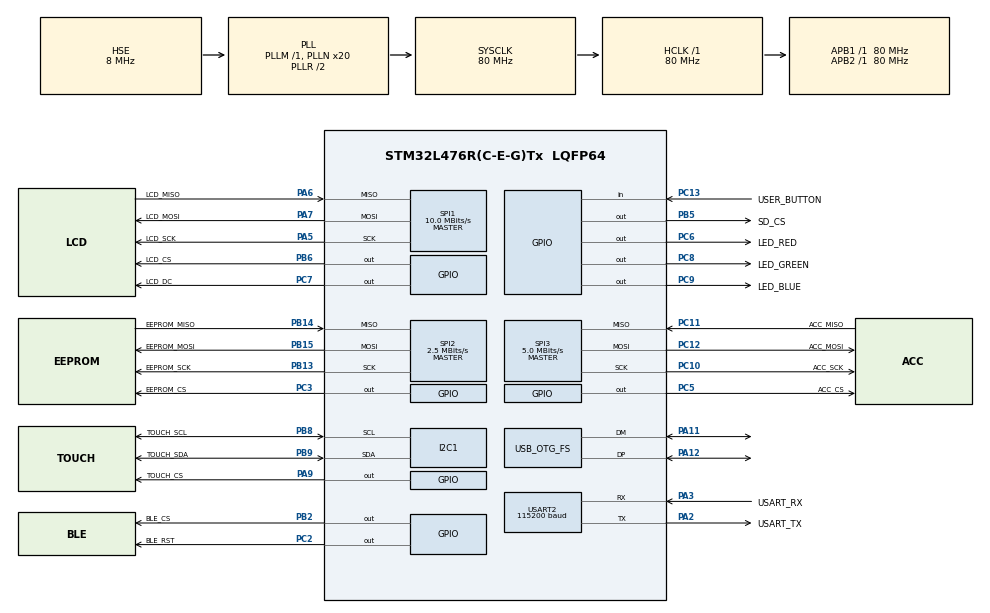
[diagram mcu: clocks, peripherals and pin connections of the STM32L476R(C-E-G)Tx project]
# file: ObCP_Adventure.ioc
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Dma.Request0=SPI1_TX
Dma.SPI1_TX.0.Direction=DMA_MEMORY_TO_PERIPH
Dma.SPI1_TX.0.Instance=DMA1_Channel3
Dma.SPI1_TX.0.MemDataAlignment=DMA_MDATAALIGN_BYTE
Dma.SPI1_TX.0.MemInc=DMA_MINC_ENABLE
Dma.SPI1_TX.0.Mode=DMA_NORMAL
Dma.SPI1_TX.0.PeriphDataAlignment=DMA_PDATAALIGN_BYTE
Dma.SPI1_TX.0.PeriphInc=DMA_PINC_DISABLE
Dma.SPI1_TX.0.Priority=DMA_PRIORITY_HIGH
I2C1.Timing=0x10909CEC
Mcu.Family=STM32L4
Mcu.Name=STM32L476R(C-E-G)Tx
Mcu.Package=LQFP64
NVIC.DMA1_Channel3_IRQn=true\:2\:0\:false\:false\:true\:false\:true\:true
NVIC.OTG_FS_IRQn=true\:0\:0\:false\:false\:true\:false\:true\:true
NVIC.PriorityGroup=NVIC_PRIORITYGROUP_4
PA11.Mode=Device_Only
PA11.Signal=USB_OTG_FS_DM
PA12.Mode=Device_Only
PA12.Signal=USB_OTG_FS_DP
PA13\ (JTMS-SWDIO).GPIO_Label=TMS
PA13\ (JTMS-SWDIO).Mode=Serial_Wire
PA13\ (JTMS-SWDIO).Signal=SYS_JTMS-SWDIO
PA14\ (JTCK-SWCLK).GPIO_Label=TCK
PA14\ (JTCK-SWCLK).Mode=Serial_Wire
PA14\ (JTCK-SWCLK).Signal=SYS_JTCK-SWCLK
PA2.GPIO_Label=USART_TX
PA2.Mode=Asynchronous
PA2.Signal=USART2_TX
PA3.GPIO_Label=USART_RX
PA3.Mode=Asynchronous
PA3.Signal=USART2_RX
PA5.GPIO_Label=LCD_SCK
PA5.Mode=Full_Duplex_Master
PA5.Signal=SPI1_SCK
PA6.GPIO_Label=LCD_MISO
PA6.Mode=Full_Duplex_Master
PA6.Signal=SPI1_MISO
PA7.GPIO_Label=LCD_MOSI
PA7.Mode=Full_Duplex_Master
PA7.Signal=SPI1_MOSI
PA9.GPIO_Label=TOUCH_CS
PA9.GPIO_Speed=GPIO_SPEED_FREQ_HIGH
PA9.PinState=GPIO_PIN_SET
PA9.Signal=GPIO_Output
PB13.GPIO_Label=EEPROM_SCK
PB13.Mode=Full_Duplex_Master
PB13.Signal=SPI2_SCK
PB14.GPIO_Label=EEPROM_MISO
PB14.Mode=Full_Duplex_Master
PB14.Signal=SPI2_MISO
PB15.GPIO_Label=EEPROM_MOSI
PB15.Mode=Full_Duplex_Master
PB15.Signal=SPI2_MOSI
PB2.GPIO_Label=BLE_CS
PB2.PinState=GPIO_PIN_SET
PB2.Signal=GPIO_Output
PB5.GPIO_Label=SD_CS
PB5.PinState=GPIO_PIN_SET
PB5.Signal=GPIO_Output
PB6.GPIO_Label=LCD_CS
PB6.GPIO_Speed=GPIO_SPEED_FREQ_HIGH
PB6.PinState=GPIO_PIN_SET
PB6.Signal=GPIO_Output
PB8.GPIO_Label=TOUCH_SCL
PB8.Mode=I2C
PB8.Signal=I2C1_SCL
PB9.GPIO_Label=TOUCH_SDA
PB9.Mode=I2C
PB9.Signal=I2C1_SDA
PC10.GPIO_Label=ACC_SCK
PC10.Mode=Full_Duplex_Master
PC10.Signal=SPI3_SCK
PC11.GPIO_Label=ACC_MISO
PC11.Mode=Full_Duplex_Master
PC11.Signal=SPI3_MISO
PC12.GPIO_Label=ACC_MOSI
PC12.Mode=Full_Duplex_Master
PC12.Signal=SPI3_MOSI
PC13.GPIO_Label=USER_BUTTON
PC13.Signal=GPIO_Input
PC2.GPIO_Label=BLE_RST
PC2.Signal=GPIO_Output
PC3.GPIO_Label=EEPROM_CS
PC3.GPIO_Speed=GPIO_SPEED_FREQ_HIGH
PC3.PinState=GPIO_PIN_SET
PC3.Signal=GPIO_Output
PC5.GPIO_Label=ACC_CS
PC5.GPIO_Speed=GPIO_SPEED_FREQ_HIGH
PC5.PinState=GPIO_PIN_SET
PC5.Signal=GPIO_Output
PC6.GPIO_Label=LED_RED
PC6.Signal=GPIO_Output
PC7.GPIO_Label=LCD_DC
PC7.GPIO_Speed=GPIO_SPEED_FREQ_HIGH
PC7.Signal=GPIO_Output
PC8.GPIO_Label=LED_GREEN
PC8.Signal=GPIO_Output
PC9.GPIO_Label=LED_BLUE
PC9.Signal=GPIO_Output
PH0-OSC_IN\ (PH0).Mode=HSE-External-Oscillator
PH0-OSC_IN\ (PH0).Signal=RCC_OSC_IN
PH1-OSC_OUT\ (PH1).Mode=HSE-External-Oscillator
PH1-OSC_OUT\ (PH1).Signal=RCC_OSC_OUT
ProjectManager.HeapSize=0x200
ProjectManager.StackSize=0x2000
ProjectManager.TargetToolchain=STM32CubeIDE
RCC.ADCFreq_Value=48000000
RCC.AHBFreq_Value=80000000
RCC.APB1Freq_Value=80000000
RCC.APB1TimFreq_Value=80000000
RCC.APB2Freq_Value=80000000
RCC.APB2TimFreq_Value=80000000
RCC.CortexFreq_Value=80000000
RCC.HCLKFreq_Value=80000000
RCC.HSE_VALUE=8000000
RCC.HSI_VALUE=16000000
RCC.LSE_VALUE=32768
RCC.MSI_VALUE=4000000
RCC.PLLN=20
RCC.PLLSAI1N=12
RCC.PLLSourceVirtual=RCC_PLLSOURCE_HSE
RCC.PREFETCH_ENABLE=1
RCC.SYSCLKFreq_VALUE=80000000
RCC.SYSCLKSource=RCC_SYSCLKSOURCE_PLLCLK
RCC.USBFreq_Value=48000000
RCC.VCOOutputFreq_Value=160000000
SPI1.BaudRatePrescaler=SPI_BAUDRATEPRESCALER_8
SPI1.CLKPhase=SPI_PHASE_1EDGE
SPI1.CLKPolarity=SPI_POLARITY_LOW
SPI1.CalculateBaudRate=10.0 MBits/s
SPI1.DataSize=SPI_DATASIZE_8BIT
SPI1.Direction=SPI_DIRECTION_2LINES
SPI1.Mode=SPI_MODE_MASTER
SPI1.NSSPMode=SPI_NSS_PULSE_DISABLE
SPI1.VirtualType=VM_MASTER
SPI2.BaudRatePrescaler=SPI_BAUDRATEPRESCALER_32
SPI2.CLKPhase=SPI_PHASE_1EDGE
SPI2.CLKPolarity=SPI_POLARITY_LOW
SPI2.CalculateBaudRate=2.5 MBits/s
SPI2.DataSize=SPI_DATASIZE_8BIT
SPI2.Direction=SPI_DIRECTION_2LINES
SPI2.Mode=SPI_MODE_MASTER
SPI2.NSSPMode=SPI_NSS_PULSE_DISABLE
SPI2.VirtualType=VM_MASTER
SPI3.BaudRatePrescaler=SPI_BAUDRATEPRESCALER_16
SPI3.CLKPhase=SPI_PHASE_2EDGE
SPI3.CLKPolarity=SPI_POLARITY_HIGH
SPI3.CalculateBaudRate=5.0 MBits/s
SPI3.DataSize=SPI_DATASIZE_8BIT
SPI3.Direction=SPI_DIRECTION_2LINES
SPI3.Mode=SPI_MODE_MASTER
SPI3.VirtualType=VM_MASTER
TIM2.Period=4294967295
TIM2.Prescaler=79
USART2.BaudRate=115200
USART2.VirtualMode-Asynchronous=VM_ASYNC
USB_DEVICE.CLASS_NAME_FS=CDC
USB_DEVICE.LANGID_STRING=1036
USB_DEVICE.MANUFACTURER_STRING=SupMicrotech_CROC
USB_DEVICE.PRODUCT_STRING_CDC_FS=SupMicrotech_CROC
USB_DEVICE.VirtualMode=Cdc
USB_DEVICE.VirtualModeFS=Cdc_FS
USB_OTG_FS.VirtualMode=Device_Only
VP_TIM2_VS_ClockSourceINT.Mode=Internal
VP_USB_DEVICE_VS_USB_DEVICE_CDC_FS.Mode=CDC_FS
board=custom

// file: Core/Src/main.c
/* USER CODE BEGIN Header */
/**
  ******************************************************************************
  * @file           : main.c
  * @brief          : Point d'entrée d'ObCP Adventure (jeu de plateformes sur
  *                   écran tactile pour l'ObCP, version 1.0.0).
  ******************************************************************************
  *  Ce fichier est GÉNÉRÉ par STM32CubeMX à partir de ObCP_Adventure.ioc.
  *  À chaque génération, CubeMX le réécrit en gardant uniquement ce qui est
  *  placé entre les commentaires « USER CODE BEGIN xxx » et
  *  « USER CODE END xxx ». Le jeu est donc rangé dans d'autres fichiers
  *  (Core/Src/app, engine, graphics, services, devices...) et relié ici par
  *  trois lignes :
  *    - oa_app_init();    (section USER CODE 2) : démarrage du jeu ;
  *    - oa_app_task();    (section USER CODE 3) : un tour de super-boucle ;
  *    - oa_board_fatal(); (Error_Handler)       : erreur grave, LED rouge.
  *
  *  Ordre de lecture conseillé :
  *    1. main.c (ce fichier)      : ordre du démarrage ;
  *    2. app/oa_app.c             : ordonnanceur (entrées, physique, rendu) ;
  *    3. engine/oa_game.c         : règles du jeu et machine à états ;
  *    4. engine/oa_physics.c      : déplacements et collisions ;
  *    5. graphics/oa_render.c     : dessin d'une bande de 8 lignes ;
  *    6. oa_board.c               : bus SPI/I2C, DMA de l'écran (seul fichier
  *                                  du jeu qui appelle la HAL).
  *  Dans STM32CubeIDE : Ctrl + clic sur un nom de fonction ouvre sa
  *  définition ; Ctrl + Alt + H affiche les fonctions qui l'appellent.
  ******************************************************************************
  * @attention
  *
  * Copyright (c) 2026 STMicroelectronics.
  * All rights reserved.
  *
  * This software is licensed under terms that can be found in the LICENSE file
  * in the root directory of this software component.
  * If no LICENSE file comes with this software, it is provided AS-IS.
  *
  ******************************************************************************
  */
/* USER CODE END Header */
#include "main.h"
#include "dma.h"
#include "i2c.h"
#include "spi.h"
#include "tim.h"
#include "usart.h"
#include "usb_device.h"
#include "gpio.h"

/* USER CODE BEGIN Includes */
#include "oa_app.h"
#include "oa_board.h"
/* USER CODE END Includes */

void SystemClock_Config(void);

int main(void)
{

  /* MCU Configuration--------------------------------------------------------*/

  /* Reset of all peripherals, Initializes the Flash interface and the Systick. */
  HAL_Init();

  /* Configure the system clock */
  SystemClock_Config();

  /* Initialize all configured peripherals */
  MX_GPIO_Init();
  MX_DMA_Init();
  MX_SPI1_Init();
  MX_SPI2_Init();
  MX_SPI3_Init();
  MX_I2C1_Init();
  MX_TIM2_Init();
  MX_USART2_UART_Init();
  MX_USB_DEVICE_Init();
  /* USER CODE BEGIN 2 */
  /* Toute la configuration générée est faite : on démarre le jeu (base de
   * temps TIM2, sauvegarde, tactile, accéléromètre, écran), voir oa_app.c. */
  oa_app_init();

  /* USER CODE END 2 */

  /* Infinite loop */
  while (1)
  {

    /* USER CODE BEGIN 3 */
    oa_app_task();                  /* un tour de la super-boucle (oa_app.c) */
  }
  /* USER CODE END 3 */
}

void SystemClock_Config(void)
{
  RCC_OscInitTypeDef RCC_OscInitStruct = {0};
  RCC_ClkInitTypeDef RCC_ClkInitStruct = {0};

  /** Configure the main internal regulator output voltage
  */
  if (HAL_PWREx_ControlVoltageScaling(PWR_REGULATOR_VOLTAGE_SCALE1) != HAL_OK)
  {
    Error_Handler();
  }

  /** Initializes the RCC Oscillators according to the specified parameters
  * in the RCC_OscInitTypeDef structure.
  */
  RCC_OscInitStruct.OscillatorType = RCC_OSCILLATORTYPE_HSE;
  RCC_OscInitStruct.HSEState = RCC_HSE_ON;
  RCC_OscInitStruct.PLL.PLLState = RCC_PLL_ON;
  RCC_OscInitStruct.PLL.PLLSource = RCC_PLLSOURCE_HSE;
  RCC_OscInitStruct.PLL.PLLM = 1;
  RCC_OscInitStruct.PLL.PLLN = 20;
  RCC_OscInitStruct.PLL.PLLP = RCC_PLLP_DIV7;
  RCC_OscInitStruct.PLL.PLLQ = RCC_PLLQ_DIV2;
  RCC_OscInitStruct.PLL.PLLR = RCC_PLLR_DIV2;
  if (HAL_RCC_OscConfig(&RCC_OscInitStruct) != HAL_OK)
  {
    Error_Handler();
  }

  /** Initializes the CPU, AHB and APB buses clocks
  */
  RCC_ClkInitStruct.ClockType = RCC_CLOCKTYPE_HCLK|RCC_CLOCKTYPE_SYSCLK
                              |RCC_CLOCKTYPE_PCLK1|RCC_CLOCKTYPE_PCLK2;
  RCC_ClkInitStruct.SYSCLKSource = RCC_SYSCLKSOURCE_PLLCLK;
  RCC_ClkInitStruct.AHBCLKDivider = RCC_SYSCLK_DIV1;
  RCC_ClkInitStruct.APB1CLKDivider = RCC_HCLK_DIV1;
  RCC_ClkInitStruct.APB2CLKDivider = RCC_HCLK_DIV1;

  if (HAL_RCC_ClockConfig(&RCC_ClkInitStruct, FLASH_LATENCY_4) != HAL_OK)
  {
    Error_Handler();
  }
}

void Error_Handler(void)
{
  /* USER CODE BEGIN Error_Handler_Debug */
  /* Erreur grave pendant une initialisation (horloge, SPI, I2C, USB...) :
   * interruptions coupées, LED rouge allumée en continu, arrêt (oa_board.c).
   * Seul un reset (SW3) fait repartir la carte. */
  oa_board_fatal();
  /* USER CODE END Error_Handler_Debug */
}
